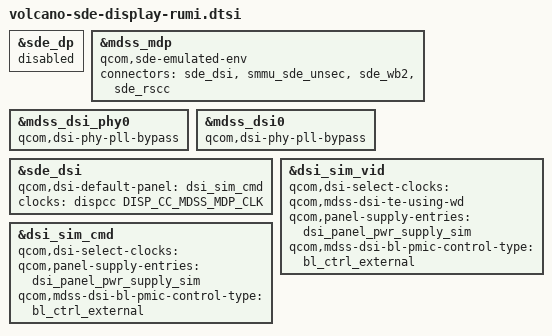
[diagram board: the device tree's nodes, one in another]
#include "volcano-sde-display.dtsi"

&sde_dp {
	status = "disabled";
};

&mdss_mdp {
	qcom,sde-emulated-env;
	connectors = <&sde_dsi &smmu_sde_unsec &sde_wb2 &sde_rscc>;
};

&mdss_dsi_phy0 {
	qcom,dsi-phy-pll-bypass;
};

&mdss_dsi0 {
	qcom,dsi-phy-pll-bypass;
};

&sde_dsi {
	qcom,dsi-default-panel = <&dsi_sim_cmd>;
	clocks = <&dispcc DISP_CC_MDSS_MDP_CLK>;
	clock-names = "mdp_core_clk";
};

&dsi_sim_vid {
	qcom,dsi-select-clocks = "";
	qcom,mdss-dsi-te-using-wd;
	qcom,panel-supply-entries = <&dsi_panel_pwr_supply_sim>;
	qcom,mdss-dsi-bl-pmic-control-type = "bl_ctrl_external";
};

&dsi_sim_cmd {
	qcom,dsi-select-clocks = "";
	qcom,panel-supply-entries = <&dsi_panel_pwr_supply_sim>;
	qcom,mdss-dsi-bl-pmic-control-type = "bl_ctrl_external";
};
